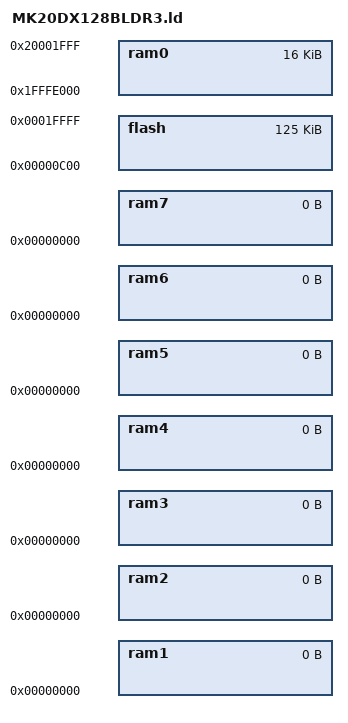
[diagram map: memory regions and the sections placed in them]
/*
 * Copyright (C) 2013-2016 Fabio Utzig, http://fabioutzig.com
 *           (C) 2016 flabbergast <s3+flabbergast@sdfeu.org>
 *
 * Permission is hereby granted, free of charge, to any person obtaining
 * a copy of this software and associated documentation files (the "Software"),
 * to deal in the Software without restriction, including without limitation
 * the rights to use, copy, modify, merge, publish, distribute, sublicense,
 * and/or sell copies of the Software, and to permit persons to whom the
 * Software is furnished to do so, subject to the following conditions:
 *
 * The above copyright notice and this permission notice shall be included in
 * all copies or substantial portions of the Software.
 *
 * THE SOFTWARE IS PROVIDED "AS IS", WITHOUT WARRANTY OF ANY KIND, EXPRESS
 * OR IMPLIED, INCLUDING BUT NOT LIMITED TO THE WARRANTIES OF MERCHANTABILITY,
 * FITNESS FOR A PARTICULAR PURPOSE AND NONINFRINGEMENT. IN NO EVENT SHALL THE
 * AUTHORS OR COPYRIGHT HOLDERS BE LIABLE FOR ANY CLAIM, DAMAGES OR OTHER
 * LIABILITY, WHETHER IN AN ACTION OF CONTRACT, TORT OR OTHERWISE, ARISING FROM,
 * OUT OF OR IN CONNECTION WITH THE SOFTWARE OR THE USE OR OTHER DEALINGS IN THE
 * SOFTWARE.
 */

/*
 * MK20DX128 memory setup (3k bootloader section).
 */
MEMORY
{
  flash    : org = 0x00000c00, len = 128k - 0xc00
  ram0     : org = 0x1FFFE000, len = 16k
  ram1     : org = 0x00000000, len = 0
  ram2     : org = 0x00000000, len = 0
  ram3     : org = 0x00000000, len = 0
  ram4     : org = 0x00000000, len = 0
  ram5     : org = 0x00000000, len = 0
  ram6     : org = 0x00000000, len = 0
  ram7     : org = 0x00000000, len = 0
}

/* RAM region to be used for Main stack. This stack accommodates the processing
   of all exceptions and interrupts*/
REGION_ALIAS("MAIN_STACK_RAM", ram0);

/* RAM region to be used for the process stack. This is the stack used by
   the main() function.*/
REGION_ALIAS("PROCESS_STACK_RAM", ram0);

/* RAM region to be used for data segment.*/
REGION_ALIAS("DATA_RAM", ram0);

/* RAM region to be used for BSS segment.*/
REGION_ALIAS("BSS_RAM", ram0);

/* RAM region to be used for the default heap.*/
REGION_ALIAS("HEAP_RAM", ram0);

INCLUDE rules_kinetis_bldr.ld
